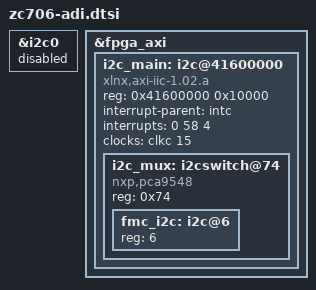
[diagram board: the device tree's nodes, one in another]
&i2c0 {
	status = "disabled";
};

&fpga_axi {
	i2c_main: i2c@41600000 {
		compatible = "xlnx,axi-iic-1.02.a", "xlnx,xps-iic-2.00.a";
		reg = <0x41600000 0x10000>;
		interrupt-parent = <&intc>;
		interrupts = <0 58 4>;
		clocks = <&clkc 15>;
		clock-names = "pclk";

		#address-cells = <1>;
		#size-cells = <0>;

		i2c_mux: i2cswitch@74 {
			compatible = "nxp,pca9548";
			#address-cells = <1>;
			#size-cells = <0>;
			reg = <0x74>;

			fmc_i2c: i2c@6 {
				#size-cells = <0>;
				#address-cells = <1>;
				reg = <6>;
			};

		};
	};
};

